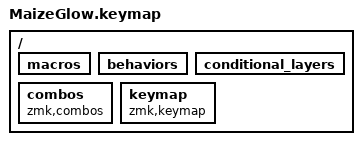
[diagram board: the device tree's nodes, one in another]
#include <behaviors.dtsi>
#include <dt-bindings/zmk/keys.h>
#include <dt-bindings/zmk/bt.h>
#include <dt-bindings/zmk/outputs.h>
#include <dt-bindings/zmk/mouse.h>
#include <dt-bindings/zmk/rgb.h>

// NICE!VIEW CONFIG
#include "settings/nice_view.keymap"

// HELPERS
#include "helpers/combos.keymap"

// PRESS SETTINGS
#include "settings/press.keymap"

// LAYERS
#include "os/layers.keymap"

// KEYS
#include "os/keys.keymap"

// PER-KEY RGB
#include "settings/rgb_layers.keymap"

// KEYBOARD
/ {
        macros {
                #include "os/macros.keymap"
        };

        behaviors {
                // #include "os/tap_dance.keymap"
        };

        conditional_layers {
                // compatible = "zmk,conditional-layers";
                // #include "os/conditional.keymap"
        };

        combos {
                compatible = "zmk,combos";
                #include "os/combos.keymap"
        };

        keymap {
                compatible = "zmk,keymap";
                #include "keymap/0_base.keymap"
                #include "keymap/1_lower.keymap"
                #include "keymap/2_raise.keymap"
                #include "keymap/3_number.keymap"
                #include "keymap/4_extra.keymap"
                #include "keymap/5_uber.keymap"
                #include "keymap/6_player.keymap"
        };
};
